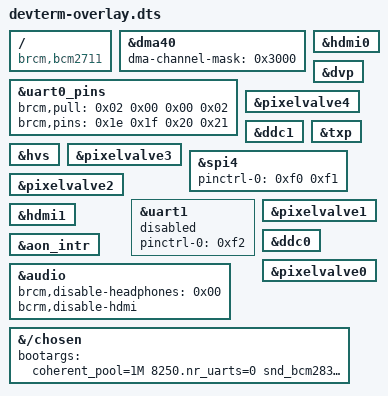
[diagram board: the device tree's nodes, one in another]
/dts-v1/;
/plugin/;

/ {
	compatible = "brcm,bcm2711";
	fragment@0 {
		target = <&dma40>;
		__overlay__ {
			dma-channel-mask = <0x3000>;
		};
	};
	fragment@1 {
		target = <&hdmi0>;
		__overlay__ {
			status = "okay";
		};
	};
	fragment@2 {
		target = <&uart0_pins>;
		__overlay__ {
			brcm,pull = <0x02 0x00 0x00 0x02>;
			brcm,pins = <0x1e 0x1f 0x20 0x21>;
		};
	};
	fragment@3 {
		target = <&dvp>;
		__overlay__ {
			status = "okay";
		};
	};
	fragment@4 {
		target = <&pixelvalve4>;
		__overlay__ {
			status = "okay";
		};
	};
	fragment@5 {
		target = <&ddc1>;
		__overlay__ {
			status = "okay";
		};
	};
	fragment@6 {
		target = <&txp>;
		__overlay__ {
			status = "okay";
		};
	};
	fragment@7 {
		target = <&hvs>;
		__overlay__ {
			status = "okay";
		};
	};
	fragment@8 {
		target = <&pixelvalve3>;
		__overlay__ {
			status = "okay";
		};
	};
	fragment@9 {
		target = <&spi4>;
		__overlay__ {
			pinctrl-0 = <0xf0 0xf1>;
		};
	};
	fragment@10 {
		target = <&pixelvalve2>;
		__overlay__ {
			status = "okay";
		};
	};
	fragment@11 {
		target = <&uart1>;
		__overlay__ {
			pinctrl-0 = <0xf2>;
			status = "disabled";
		};
	};
	fragment@12 {
		target = <&pixelvalve1>;
		__overlay__ {
			status = "okay";
		};
	};
	fragment@13 {
		target = <&hdmi1>;
		__overlay__ {
			status = "okay";
		};
	};
	fragment@14 {
		target = <&spi4>;
		__overlay__ {
			status = "okay";
		};
	};
	fragment@15 {
		target = <&ddc0>;
		__overlay__ {
			status = "okay";
		};
	};
	fragment@16 {
		target = <&aon_intr>;
		__overlay__ {
			status = "okay";
		};
	};
	fragment@17 {
		target = <&pixelvalve0>;
		__overlay__ {
			status = "okay";
		};
	};
	fragment@18 {
		target = <&audio>;
		__overlay__ {
			brcm,disable-headphones = <0x00>;
			status = "okay";
			bcrm,disable-hdmi;
		};
	};
	fragment@19 {
		target-path = "/chosen";
		__overlay__ {
			bootargs = "coherent_pool=1M 8250.nr_uarts=0 snd_bcm2835.enable_compat_alsa=0 snd_bcm2835.enable_hdmi=1 8250.nr_uarts=0  smsc95xx.macaddr=E4:5F:01:E4:FE:2D vc_mem.mem_base=0x3ec00000 vc_mem.mem_size=0x40000000 8250.nr_uarts=1";
		};
	};
};
